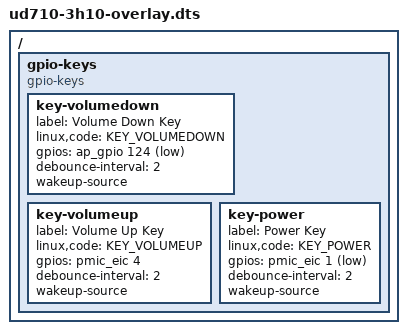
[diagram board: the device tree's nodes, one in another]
/dts-v1/;
/plugin/;

#include <dt-bindings/input/input.h>
#include <dt-bindings/gpio/gpio.h>

/ {
	fragment {
		target-path = "/";
		__overlay__ {

			gpio-keys {
				compatible = "gpio-keys";

				key-volumedown {
					label = "Volume Down Key";
					linux,code = <KEY_VOLUMEDOWN>;
					gpios = <&ap_gpio 124 GPIO_ACTIVE_LOW>;
					debounce-interval = <2>;
					wakeup-source;
				};

				key-volumeup {
					label = "Volume Up Key";
					linux,code = <KEY_VOLUMEUP>;
					gpios = <&pmic_eic 4 GPIO_ACTIVE_HIGH>;
					debounce-interval = <2>;
					wakeup-source;
				};

				key-power {
					label = "Power Key";
					linux,code = <KEY_POWER>;
					gpios = <&pmic_eic 1 GPIO_ACTIVE_LOW>;
					debounce-interval = <2>;
					wakeup-source;
				};
			};
		};
	};
};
